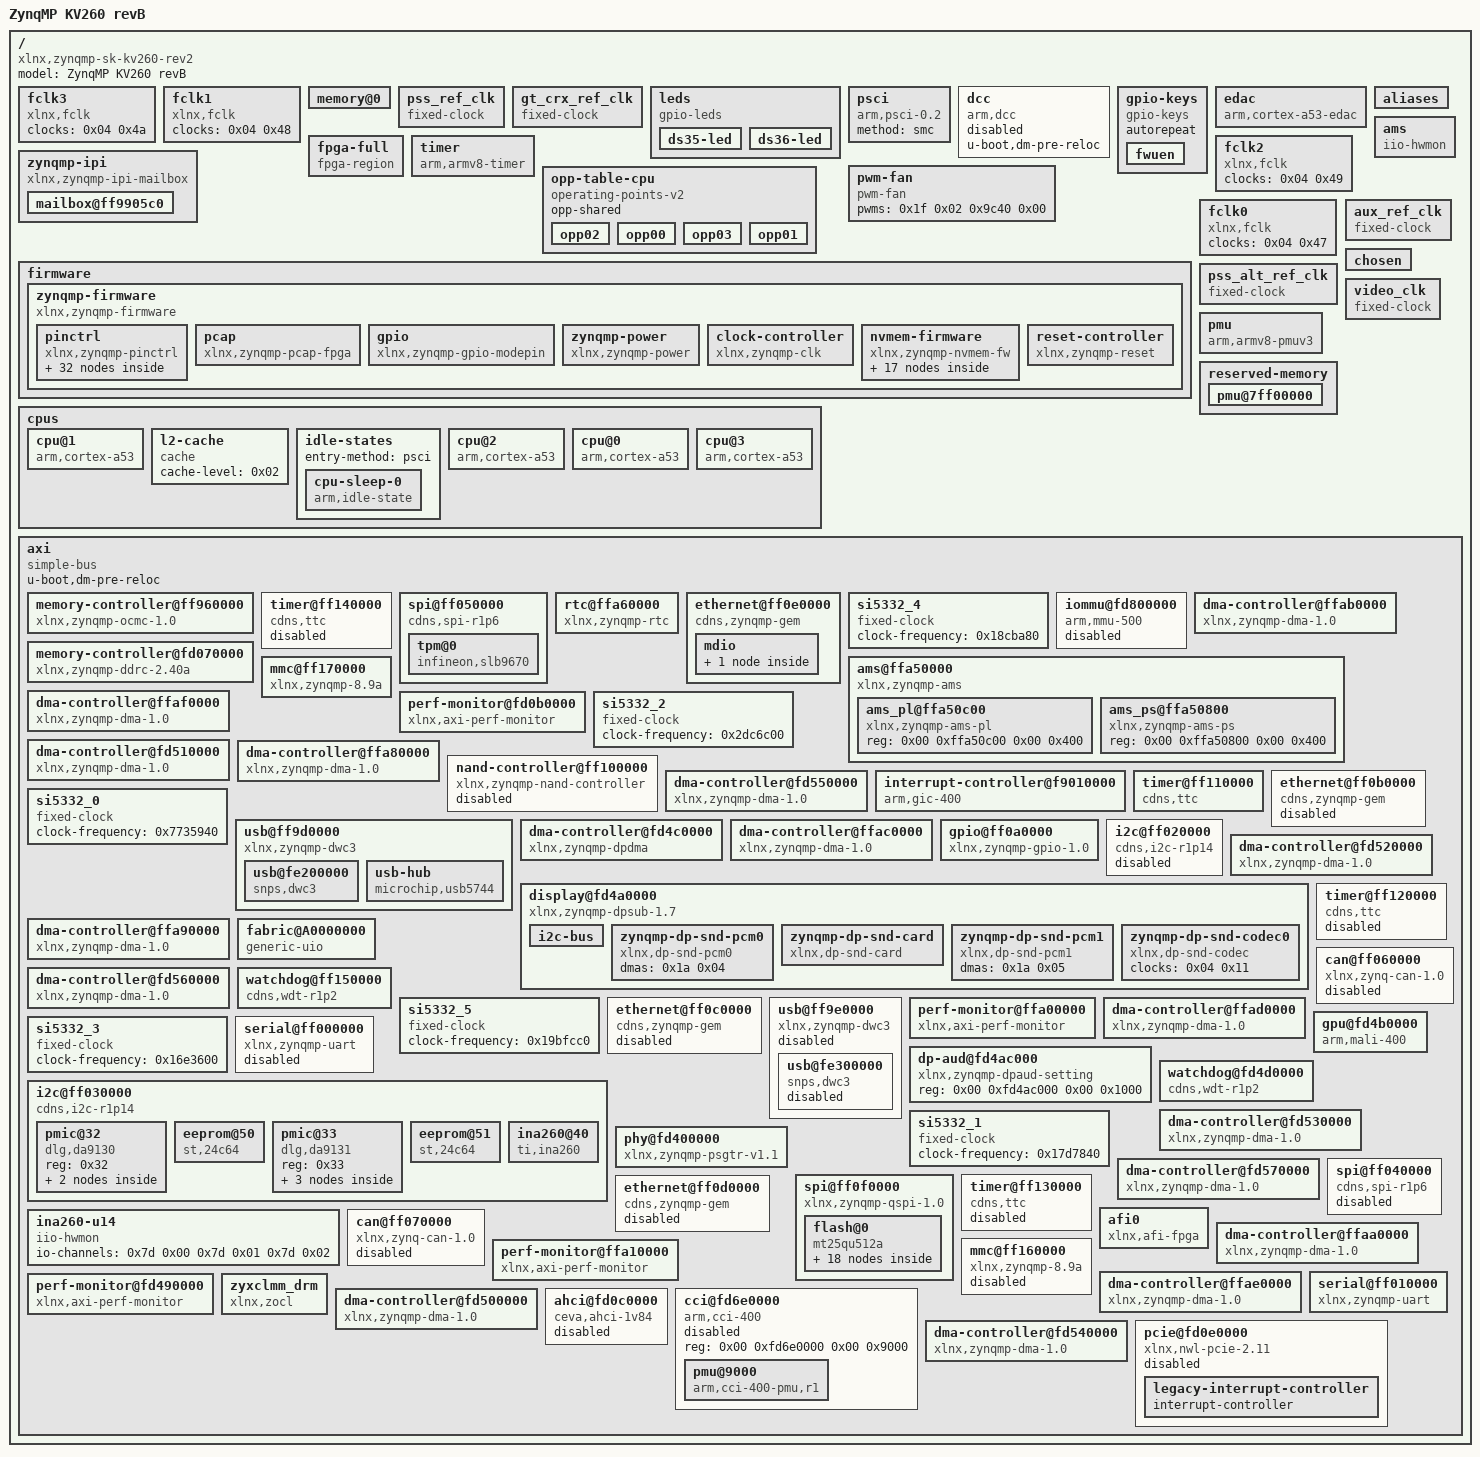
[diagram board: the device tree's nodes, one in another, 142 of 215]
/dts-v1/;

/ {
	#address-cells = <0x02>;
	model = "ZynqMP KV260 revB";
	#size-cells = <0x02>;
	compatible = "xlnx,zynqmp-sk-kv260-rev2\0xlnx,zynqmp-sk-kv260-rev1\0xlnx,zynqmp-sk-kv260-revB\0xlnx,zynqmp-sk-kv260\0xlnx,zynqmp";

	fclk3 {
		clocks = <0x04 0x4a>;
		compatible = "xlnx,fclk";
		status = "okay";
		phandle = <0x79>;
	};

	fclk1 {
		clocks = <0x04 0x48>;
		compatible = "xlnx,fclk";
		status = "okay";
		phandle = <0x77>;
	};

	memory@0 {
		device_type = "memory";
		reg = <0x00 0x00 0x00 0x7ff00000 0x08 0x00 0x00 0x80000000>;
	};

	pss_ref_clk {
		u-boot,dm-pre-reloc;
		#clock-cells = <0x00>;
		clock-frequency = <0x1fca055>;
		compatible = "fixed-clock";
		phandle = <0x0b>;
	};

	gt_crx_ref_clk {
		u-boot,dm-pre-reloc;
		#clock-cells = <0x00>;
		clock-frequency = <0x66ff300>;
		compatible = "fixed-clock";
		phandle = <0x0f>;
	};

	leds {
		compatible = "gpio-leds";

		ds35-led {
			linux,default-trigger = "heartbeat";
			label = "heartbeat";
			gpios = <0x14 0x07 0x00>;
		};

		ds36-led {
			label = "vbus_det";
			default-state = "on";
			gpios = <0x14 0x08 0x00>;
		};
	};

	psci {
		method = "smc";
		compatible = "arm,psci-0.2";
	};

	dcc {
		u-boot,dm-pre-reloc;
		compatible = "arm,dcc";
		status = "disabled";
		phandle = <0x21>;
	};

	gpio-keys {
		autorepeat;
		compatible = "gpio-keys";

		fwuen {
			autorepeat;
			wakeup-source;
			label = "fwuen";
			linux,code = <0x100>;
			gpios = <0x14 0x0c 0x01>;
		};
	};

	edac {
		compatible = "arm,cortex-a53-edac";
	};

	fpga-full {
		fpga-mgr = <0x10>;
		#address-cells = <0x02>;
		firmware-name = "k26-starter-kits.bit.bin";
		resets = <0x11 0x74 0x11 0x75 0x11 0x76 0x11 0x77>;
		#size-cells = <0x02>;
		compatible = "fpga-region";
		ranges;
		phandle = <0x35>;
	};

	timer {
		interrupts = <0x01 0x0d 0xf08 0x01 0x0e 0xf08 0x01 0x0b 0xf08 0x01 0x0a 0xf08>;
		interrupt-parent = <0x05>;
		compatible = "arm,armv8-timer";
	};

	fclk2 {
		clocks = <0x04 0x49>;
		compatible = "xlnx,fclk";
		status = "okay";
		phandle = <0x78>;
	};

	zynqmp-ipi {
		#address-cells = <0x02>;
		xlnx,ipi-id = <0x00>;
		u-boot,dm-pre-reloc;
		interrupts = <0x00 0x23 0x04>;
		#size-cells = <0x02>;
		interrupt-parent = <0x05>;
		compatible = "xlnx,zynqmp-ipi-mailbox";
		ranges;
		phandle = <0x20>;

		mailbox@ff9905c0 {
			xlnx,ipi-id = <0x04>;
			reg-names = "local_request_region\0local_response_region\0remote_request_region\0remote_response_region";
			u-boot,dm-pre-reloc;
			#mbox-cells = <0x01>;
			reg = <0x00 0xff9905c0 0x00 0x20 0x00 0xff9905e0 0x00 0x20 0x00 0xff990e80 0x00 0x20 0x00 0xff990ea0 0x00 0x20>;
			phandle = <0x0a>;
		};
	};

	opp-table-cpu {
		opp-shared;
		compatible = "operating-points-v2";
		phandle = <0x01>;

		opp02 {
			opp-microvolt = <0xf4240>;
			opp-hz = <0x00 0x1a7daf1c>;
			clock-latency-ns = <0x7a120>;
		};

		opp00 {
			opp-microvolt = <0xf4240>;
			opp-hz = <0x00 0x4f790d55>;
			clock-latency-ns = <0x7a120>;
		};

		opp03 {
			opp-microvolt = <0xf4240>;
			opp-hz = <0x00 0x13de4355>;
			clock-latency-ns = <0x7a120>;
		};

		opp01 {
			opp-microvolt = <0xf4240>;
			opp-hz = <0x00 0x27bc86aa>;
			clock-latency-ns = <0x7a120>;
		};
	};

	pwm-fan {
		compatible = "pwm-fan";
		status = "okay";
		pwms = <0x1f 0x02 0x9c40 0x00>;
	};

	aliases {
		spi2 = "/axi/spi@ff050000";
		i2c1 = "/axi/i2c@ff030000";
		spi0 = "/axi/spi@ff0f0000";
		mmc1 = "/axi/mmc@ff170000";
		usb1 = "/axi/usb@ff9e0000";
		nvmem0 = "/axi/i2c@ff030000/eeprom@50";
		serial1 = "/axi/serial@ff010000";
		rtc0 = "/axi/rtc@ffa60000";
		spi1 = "/axi/spi@ff040000";
		i2c0 = "/axi/i2c@ff020000";
		mmc0 = "/axi/mmc@ff160000";
		usb0 = "/axi/usb@ff9d0000";
		nvmem1 = "/axi/i2c@ff030000/eeprom@51";
		serial2 = "/dcc";
		serial0 = "/axi/serial@ff000000";
	};

	firmware {

		zynqmp-firmware {
			method = "smc";
			u-boot,dm-pre-reloc;
			#power-domain-cells = <0x01>;
			compatible = "xlnx,zynqmp-firmware";
			phandle = <0x12>;

			pinctrl {
				compatible = "xlnx,zynqmp-pinctrl";
				status = "okay";
				phandle = <0x34>;

				usb0-default {
					phandle = <0x81>;

					mux {
						function = "usb0";
						groups = "usb0_0_grp";
					};

					conf {
						groups = "usb0_0_grp";
						power-source = <0x01>;
					};

					conf-tx {
						pins = "MIO54\0MIO56\0MIO57\0MIO58\0MIO59\0MIO60\0MIO61\0MIO62\0MIO63";
						drive-strength = <0x04>;
						bias-disable;
						slew-rate = <0x01>;
					};

					conf-rx {
						pins = "MIO52\0MIO53\0MIO55";
						drive-strength = <0x0c>;
						bias-high-impedance;
						slew-rate = <0x00>;
					};
				};

				sdhci1-default {
					phandle = <0x82>;

					mux-cd {
						function = "sdio1_cd";
						groups = "sdio1_cd_0_grp";
					};

					conf-cd {
						bias-high-impedance;
						slew-rate = <0x01>;
						bias-pull-up;
						groups = "sdio1_cd_0_grp";
						power-source = <0x01>;
					};

					mux {
						function = "sdio1";
						groups = "sdio1_0_grp";
					};

					conf {
						bias-disable;
						slew-rate = <0x01>;
						groups = "sdio1_0_grp";
						power-source = <0x01>;
					};
				};

				i2c1-default {
					phandle = <0x7b>;

					mux {
						function = "i2c1";
						groups = "i2c1_6_grp";
					};

					conf {
						slew-rate = <0x01>;
						bias-pull-up;
						groups = "i2c1_6_grp";
						power-source = <0x01>;
					};
				};

				uart1-default {
					phandle = <0x85>;

					mux {
						function = "uart1";
						groups = "uart1_9_grp";
					};

					conf {
						drive-strength = <0x0c>;
						slew-rate = <0x01>;
						groups = "uart1_9_grp";
						power-source = <0x01>;
					};

					conf-tx {
						pins = "MIO36";
						bias-disable;
					};

					conf-rx {
						pins = "MIO37";
						bias-high-impedance;
					};
				};

				i2c1-gpio {
					phandle = <0x7c>;

					mux {
						function = "gpio0";
						groups = "gpio0_24_grp\0gpio0_25_grp";
					};

					conf {
						slew-rate = <0x01>;
						groups = "gpio0_24_grp\0gpio0_25_grp";
						power-source = <0x01>;
					};
				};

				gem3-default {
					phandle = <0x83>;

					mux {
						function = "ethernet3";
						groups = "ethernet3_0_grp";
					};

					conf-bootstrap {
						low-power-disable;
						pins = "MIO71\0MIO73\0MIO75";
						bias-disable;
					};

					conf {
						slew-rate = <0x01>;
						groups = "ethernet3_0_grp";
						power-source = <0x01>;
					};

					mux-mdio {
						function = "mdio3";
						groups = "mdio3_0_grp";
					};

					conf-mdio {
						bias-disable;
						slew-rate = <0x01>;
						groups = "mdio3_0_grp";
						power-source = <0x01>;
					};

					conf-tx {
						pins = "MIO64\0MIO65\0MIO66\0MIO67\0MIO68\0MIO69";
						bias-disable;
						low-power-enable;
					};

					conf-rx {
						low-power-disable;
						pins = "MIO70\0MIO72\0MIO74";
						bias-high-impedance;
					};
				};

				sdhci0-default {
					phandle = <0x17>;

					mux {
						function = "sdio0";
						groups = "sdio0_0_grp";
					};

					conf {
						bias-disable;
						slew-rate = <0x01>;
						groups = "sdio0_0_grp";
						power-source = <0x01>;
					};
				};
			};

			pcap {
				compatible = "xlnx,zynqmp-pcap-fpga";
				phandle = <0x10>;
			};

			gpio {
				gpio-controller;
				label = "modepin";
				compatible = "xlnx,zynqmp-gpio-modepin";
				phandle = <0x18>;
				#gpio-cells = <0x02>;
			};

			zynqmp-power {
				u-boot,dm-pre-reloc;
				interrupts = <0x00 0x23 0x04>;
				interrupt-parent = <0x05>;
				compatible = "xlnx,zynqmp-power";
				phandle = <0x22>;
				mboxes = <0x0a 0x00 0x0a 0x01>;
				mbox-names = "tx\0rx";
			};

			clock-controller {
				clock-names = "pss_ref_clk\0video_clk\0pss_alt_ref_clk\0aux_ref_clk\0gt_crx_ref_clk";
				u-boot,dm-pre-reloc;
				clocks = <0x0b 0x0c 0x0d 0x0e 0x0f>;
				#clock-cells = <0x01>;
				compatible = "xlnx,zynqmp-clk";
				phandle = <0x04>;
			};

			nvmem-firmware {
				#address-cells = <0x01>;
				#size-cells = <0x01>;
				compatible = "xlnx,zynqmp-nvmem-fw";

				efuse-usr3@2c {
					reg = <0x2c 0x04>;
					phandle = <0x28>;
				};

				efuse-ppk1hash@d0 {
					reg = <0xd0 0x30>;
					phandle = <0x33>;
				};

				efuse-sec@58 {
					reg = <0x58 0x04>;
					phandle = <0x30>;
				};

				efuse-ppk0hash@a0 {
					reg = <0xa0 0x30>;
					phandle = <0x32>;
				};

				efuse-usr1@24 {
					reg = <0x24 0x04>;
					phandle = <0x26>;
				};

				efuse-miscusr@40 {
					reg = <0x40 0x04>;
					phandle = <0x2d>;
				};

				efuse-usr6@38 {
					reg = <0x38 0x04>;
					phandle = <0x2b>;
				};

				efuse-usr4@30 {
					reg = <0x30 0x04>;
					phandle = <0x29>;
				};

				efuse-dna@c {
					reg = <0x0c 0x0c>;
					phandle = <0x24>;
				};

				soc-revision@0 {
					reg = <0x00 0x04>;
					phandle = <0x23>;
				};

				efuse-spkid@5c {
					reg = <0x5c 0x04>;
					phandle = <0x31>;
				};

				efuse-chash@50 {
					reg = <0x50 0x04>;
					phandle = <0x2e>;
				};

				efuse-pufmisc@54 {
					reg = <0x54 0x04>;
					phandle = <0x2f>;
				};

				efuse-usr7@3c {
					reg = <0x3c 0x04>;
					phandle = <0x2c>;
				};

				efuse-usr2@28 {
					reg = <0x28 0x04>;
					phandle = <0x27>;
				};

				efuse-usr0@20 {
					reg = <0x20 0x04>;
					phandle = <0x25>;
				};

				efuse-usr5@34 {
					reg = <0x34 0x04>;
					phandle = <0x2a>;
				};
			};

			reset-controller {
				#reset-cells = <0x01>;
				compatible = "xlnx,zynqmp-reset";
				phandle = <0x11>;
			};
		};
	};

	fclk0 {
		clocks = <0x04 0x47>;
		compatible = "xlnx,fclk";
		status = "okay";
		phandle = <0x76>;
	};

	pss_alt_ref_clk {
		u-boot,dm-pre-reloc;
		#clock-cells = <0x00>;
		clock-frequency = <0x00>;
		compatible = "fixed-clock";
		phandle = <0x0d>;
	};

	ams {
		io-channels = <0x1e 0x00 0x1e 0x01 0x1e 0x02 0x1e 0x03 0x1e 0x04 0x1e 0x05 0x1e 0x06 0x1e 0x07 0x1e 0x08 0x1e 0x09 0x1e 0x0a 0x1e 0x0b 0x1e 0x0c 0x1e 0x0d 0x1e 0x0e 0x1e 0x0f 0x1e 0x10 0x1e 0x11 0x1e 0x12 0x1e 0x13 0x1e 0x14 0x1e 0x15 0x1e 0x16 0x1e 0x17 0x1e 0x18 0x1e 0x19 0x1e 0x1a 0x1e 0x1b 0x1e 0x1c 0x1e 0x1d>;
		compatible = "iio-hwmon";
	};

	aux_ref_clk {
		u-boot,dm-pre-reloc;
		#clock-cells = <0x00>;
		clock-frequency = <0x19bfcc0>;
		compatible = "fixed-clock";
		phandle = <0x0e>;
	};

	chosen {
		linux,initrd-end = <0x00 0x78fffb2d>;
		bootargs = " root=LABEL=writable rootwait earlycon console=ttyPS1,115200 console=tty1 clk_ignore_unused uio_pdrv_genirq.of_id=generic-uio xilinx_tsn_ep.st_pcp=4 cma=1000M ";
		linux,initrd-start = <0x00 0x75de5000>;
		stdout-path = "serial1:115200n8";
	};

	video_clk {
		u-boot,dm-pre-reloc;
		#clock-cells = <0x00>;
		clock-frequency = <0x19bfcc0>;
		compatible = "fixed-clock";
		phandle = <0x0c>;
	};

	pmu {
		interrupt-affinity = <0x06 0x07 0x08 0x09>;
		interrupts = <0x00 0x8f 0x04 0x00 0x90 0x04 0x00 0x91 0x04 0x00 0x92 0x04>;
		interrupt-parent = <0x05>;
		compatible = "arm,armv8-pmuv3";
	};

	cpus {
		#address-cells = <0x01>;
		#size-cells = <0x00>;

		cpu@1 {
			cpu-idle-states = <0x02>;
			device_type = "cpu";
			compatible = "arm,cortex-a53";
			next-level-cache = <0x03>;
			reg = <0x01>;
			enable-method = "psci";
			phandle = <0x07>;
			operating-points-v2 = <0x01>;
		};

		l2-cache {
			cache-level = <0x02>;
			compatible = "cache";
			phandle = <0x03>;
		};

		idle-states {
			entry-method = "psci";

			cpu-sleep-0 {
				entry-latency-us = <0x12c>;
				local-timer-stop;
				exit-latency-us = <0x258>;
				arm,psci-suspend-param = <0x40000000>;
				compatible = "arm,idle-state";
				phandle = <0x02>;
				min-residency-us = <0x2710>;
			};
		};

		cpu@2 {
			cpu-idle-states = <0x02>;
			device_type = "cpu";
			compatible = "arm,cortex-a53";
			next-level-cache = <0x03>;
			reg = <0x02>;
			enable-method = "psci";
			phandle = <0x08>;
			operating-points-v2 = <0x01>;
		};

		cpu@0 {
			clocks = <0x04 0x0a>;
			cpu-idle-states = <0x02>;
			device_type = "cpu";
			compatible = "arm,cortex-a53";
			next-level-cache = <0x03>;
			reg = <0x00>;
			enable-method = "psci";
			phandle = <0x06>;
			operating-points-v2 = <0x01>;
		};

		cpu@3 {
			cpu-idle-states = <0x02>;
			device_type = "cpu";
			compatible = "arm,cortex-a53";
			next-level-cache = <0x03>;
			reg = <0x03>;
			enable-method = "psci";
			phandle = <0x09>;
			operating-points-v2 = <0x01>;
		};
	};

	__symbols__ {
		efuse_usr0 = "/firmware/zynqmp-firmware/nvmem-firmware/efuse-usr0@20";
		fpd_dma_chan3 = "/axi/dma-controller@fd520000";
		mdio = "/axi/ethernet@ff0e0000/mdio";
		efuse_ppk0hash = "/firmware/zynqmp-firmware/nvmem-firmware/efuse-ppk0hash@a0";
		ams_ps = "/axi/ams@ffa50000/ams_ps@ffa50800";
		nand0 = "/axi/nand-controller@ff100000";
		fclk3 = "/fclk3";
		zynqmp_pcap = "/firmware/zynqmp-firmware/pcap";
		si5332_4 = "/axi/si5332_4";
		CPU_SLEEP_0 = "/cpus/idle-states/cpu-sleep-0";
		efuse_chash = "/firmware/zynqmp-firmware/nvmem-firmware/efuse-chash@50";
		ipi_mailbox_pmu1 = "/zynqmp-ipi/mailbox@ff9905c0";
		i2c1 = "/axi/i2c@ff030000";
		fpd_dma_chan1 = "/axi/dma-controller@fd500000";
		efuse_sec = "/firmware/zynqmp-firmware/nvmem-firmware/efuse-sec@58";
		pinctrl_sdhci1_default = "/firmware/zynqmp-firmware/pinctrl/sdhci1-default";
		ttc3 = "/axi/timer@ff140000";
		da9131 = "/axi/i2c@ff030000/pmic@33";
		qspi = "/axi/spi@ff0f0000";
		zynqmp_dp_snd_pcm0 = "/axi/display@fd4a0000/zynqmp-dp-snd-pcm0";
		fclk1 = "/fclk1";
		gpu = "/axi/gpu@fd4b0000";
		spi0 = "/axi/spi@ff040000";
		si5332_2 = "/axi/si5332_2";
		lpd_dma_chan8 = "/axi/dma-controller@ffaf0000";
		pinctrl_i2c1_default = "/firmware/zynqmp-firmware/pinctrl/i2c1-default";
		efuse_usr7 = "/firmware/zynqmp-firmware/nvmem-firmware/efuse-usr7@3c";
		gpio = "/axi/gpio@ff0a0000";
		zynqmp_clk = "/firmware/zynqmp-firmware/clock-controller";
		usb1 = "/axi/usb@ff9e0000";
		ttc1 = "/axi/timer@ff120000";
		amba = "/axi";
		usb5744 = "/axi/usb@ff9d0000/usb-hub";
		efuse_spkid = "/firmware/zynqmp-firmware/nvmem-firmware/efuse-spkid@5c";
		pss_ref_clk = "/pss_ref_clk";
		si5332_0 = "/axi/si5332_0";
		lpd_dma_chan6 = "/axi/dma-controller@ffad0000";
		efuse_usr5 = "/firmware/zynqmp-firmware/nvmem-firmware/efuse-usr5@34";
		fpd_dma_chan8 = "/axi/dma-controller@fd570000";
		efuse_ppk1hash = "/firmware/zynqmp-firmware/nvmem-firmware/efuse-ppk1hash@d0";
		gem3 = "/axi/ethernet@ff0e0000";
		cpu3 = "/cpus/cpu@3";
		zynqmp_dpaud_setting = "/axi/dp-aud@fd4ac000";
		dwc3_0 = "/axi/usb@ff9d0000/usb@fe200000";
		da9131_buck2 = "/axi/i2c@ff030000/pmic@33/regulators/buck2";
		perf_monitor_cci = "/axi/perf-monitor@fd490000";
		lpd_dma_chan4 = "/axi/dma-controller@ffab0000";
		efuse_usr3 = "/firmware/zynqmp-firmware/nvmem-firmware/efuse-usr3@2c";
		fpd_dma_chan6 = "/axi/dma-controller@fd550000";
		gt_crx_ref_clk = "/gt_crx_ref_clk";
		gic = "/axi/interrupt-controller@f9010000";
		gem1 = "/axi/ethernet@ff0c0000";
		sata = "/axi/ahci@fd0c0000";
		cpu1 = "/cpus/cpu@1";
		xilinx_ams = "/axi/ams@ffa50000";
		pinctrl_gem3_default = "/firmware/zynqmp-firmware/pinctrl/gem3-default";
		perf_monitor_lpd = "/axi/perf-monitor@ffa10000";
		uart0 = "/axi/serial@ff000000";
		zynqmp_dp_snd_codec0 = "/axi/display@fd4a0000/zynqmp-dp-snd-codec0";
		dcc = "/dcc";
		lpd_dma_chan2 = "/axi/dma-controller@ffa90000";
		ams_pl = "/axi/ams@ffa50000/ams_pl@ffa50c00";
		L2 = "/cpus/l2-cache";
		efuse_usr1 = "/firmware/zynqmp-firmware/nvmem-firmware/efuse-usr1@24";
		fpd_dma_chan4 = "/axi/dma-controller@fd530000";
		cci = "/axi/cci@fd6e0000";
		perf_monitor_ddr = "/axi/perf-monitor@fd0b0000";
		cpu_opp_table = "/opp-table-cpu";
		can0 = "/axi/can@ff060000";
		pcie = "/axi/pcie@fd0e0000";
		sdhci0 = "/axi/mmc@ff160000";
		perf_monitor_ocm = "/axi/perf-monitor@ffa00000";
		si5332_5 = "/axi/si5332_5";
		watchdog0 = "/axi/watchdog@fd4d0000";
		fpga_full = "/fpga-full";
		pinctrl_sdhci0_default = "/firmware/zynqmp-firmware/pinctrl/sdhci0-default";
		fpd_dma_chan2 = "/axi/dma-controller@fd510000";
		zynqmp_firmware = "/firmware/zynqmp-firmware";
		zynqmp_dp_snd_pcm1 = "/axi/display@fd4a0000/zynqmp-dp-snd-pcm1";
		fclk2 = "/fclk2";
		spi1 = "/axi/spi@ff050000";
		si5332_3 = "/axi/si5332_3";
		da9130_buck1 = "/axi/i2c@ff030000/pmic@32/regulators/buck1";
		ocm = "/axi/memory-controller@ff960000";
		pinctrl_i2c1_gpio = "/firmware/zynqmp-firmware/pinctrl/i2c1-gpio";
		eeprom = "/axi/i2c@ff030000/eeprom@50";
		pinctrl_uart1_default = "/firmware/zynqmp-firmware/pinctrl/uart1-default";
		i2c0 = "/axi/i2c@ff020000";
		pmu_region = "/reserved-memory/pmu@7ff00000";
		ttc2 = "/axi/timer@ff130000";
		soc_revision = "/firmware/zynqmp-firmware/nvmem-firmware/soc-revision@0";
		da9130 = "/axi/i2c@ff030000/pmic@32";
		fclk0 = "/fclk0";
		u14 = "/axi/i2c@ff030000/ina260@40";
		pss_alt_ref_clk = "/pss_alt_ref_clk";
		si5332_1 = "/axi/si5332_1";
		lpd_dma_chan7 = "/axi/dma-controller@ffae0000";
		efuse_usr6 = "/firmware/zynqmp-firmware/nvmem-firmware/efuse-usr6@38";
		efuse_dna = "/firmware/zynqmp-firmware/nvmem-firmware/efuse-dna@c";
		aux_ref_clk = "/aux_ref_clk";
		psgtr = "/axi/phy@fd400000";
		usb0 = "/axi/usb@ff9d0000";
		ttc0 = "/axi/timer@ff110000";
		mc = "/axi/memory-controller@fd070000";
		zynqmp_dpsub = "/axi/display@fd4a0000";
		pinctrl0 = "/firmware/zynqmp-firmware/pinctrl";
		dwc3_1 = "/axi/usb@ff9e0000/usb@fe300000";
		phy0 = "/axi/ethernet@ff0e0000/mdio/ethernet-phy@1";
		lpd_dma_chan5 = "/axi/dma-controller@ffac0000";
		zynqmp_ipi = "/zynqmp-ipi";
		efuse_usr4 = "/firmware/zynqmp-firmware/nvmem-firmware/efuse-usr4@30";
		fpd_dma_chan7 = "/axi/dma-controller@fd560000";
		video_clk = "/video_clk";
		gem2 = "/axi/ethernet@ff0d0000";
		efuse_pufmisc = "/firmware/zynqmp-firmware/nvmem-firmware/efuse-pufmisc@54";
		zynqmp_dpdma = "/axi/dma-controller@fd4c0000";
		cpu2 = "/cpus/cpu@2";
		uart1 = "/axi/serial@ff010000";
		da9131_buck1 = "/axi/i2c@ff030000/pmic@33/regulators/buck1";
		efuse_miscusr = "/firmware/zynqmp-firmware/nvmem-firmware/efuse-miscusr@40";
		lpd_dma_chan3 = "/axi/dma-controller@ffaa0000";
		efuse_usr2 = "/firmware/zynqmp-firmware/nvmem-firmware/efuse-usr2@28";
		fpd_dma_chan5 = "/axi/dma-controller@fd540000";
		eeprom_cc = "/axi/i2c@ff030000/eeprom@51";
		zynqmp_dp_snd_card0 = "/axi/display@fd4a0000/zynqmp-dp-snd-card";
		zynqmp_power = "/firmware/zynqmp-firmware/zynqmp-power";
		can1 = "/axi/can@ff070000";
		gem0 = "/axi/ethernet@ff0b0000";
		pinctrl_usb0_default = "/firmware/zynqmp-firmware/pinctrl/usb0-default";
		pcie_intc = "/axi/pcie@fd0e0000/legacy-interrupt-controller";
		sdhci1 = "/axi/mmc@ff170000";
		rtc = "/axi/rtc@ffa60000";
		smmu = "/axi/iommu@fd800000";
		lpd_watchdog = "/axi/watchdog@ff150000";
		modepin_gpio = "/firmware/zynqmp-firmware/gpio";
		cpu0 = "/cpus/cpu@0";
		zynqmp_reset = "/firmware/zynqmp-firmware/reset-controller";
		lpd_dma_chan1 = "/axi/dma-controller@ffa80000";
	};

	reserved-memory {
		#address-cells = <0x02>;
		#size-cells = <0x02>;
		ranges;

		pmu@7ff00000 {
			reg = <0x00 0x7ff00000 0x00 0x100000>;
			phandle = <0x7a>;
			no-map;
		};
	};

	axi {
		#address-cells = <0x02>;
		u-boot,dm-pre-reloc;
		#size-cells = <0x02>;
		compatible = "simple-bus";
		ranges;
		phandle = <0x36>;

		memory-controller@ff960000 {
			interrupts = <0x00 0x0a 0x04>;
			interrupt-parent = <0x05>;
			compatible = "xlnx,zynqmp-ocmc-1.0";
			reg = <0x00 0xff960000 0x00 0x1000>;
			phandle = <0x5a>;
		};

		timer@ff140000 {
			power-domains = <0x12 0x1b>;
			timer-width = <0x20>;
			interrupts = <0x00 0x2d 0x04 0x00 0x2e 0x04 0x00 0x2f 0x04>;
			clocks = <0x04 0x1f>;
			interrupt-parent = <0x05>;
			compatible = "cdns,ttc";
			status = "disabled";
			reg = <0x00 0xff140000 0x00 0x1000>;
			phandle = <0x69>;
		};

		spi@ff050000 {
			power-domains = <0x12 0x24>;
			#address-cells = <0x01>;
			num-cs = <0x01>;
			clock-names = "ref_clk\0pclk";
			interrupts = <0x00 0x14 0x04>;
			clocks = <0x04 0x3b 0x04 0x1f>;
			#size-cells = <0x00>;
			interrupt-parent = <0x05>;
			label = "TPM";
			compatible = "cdns,spi-r1p6";
			status = "okay";
			reg = <0x00 0xff050000 0x00 0x1000>;
			phandle = <0x66>;

			tpm@0 {
				spi-max-frequency = <0x11a49a0>;
				compatible = "infineon,slb9670\0tcg,tpm_tis-spi";
				reg = <0x00>;
			};
		};

		rtc@ffa60000 {
			calibration = <0x7fff>;
			interrupts = <0x00 0x1a 0x04 0x00 0x1b 0x04>;
			interrupt-parent = <0x05>;
			compatible = "xlnx,zynqmp-rtc";
			status = "okay";
			interrupt-names = "alarm\0sec";
			reg = <0x00 0xffa60000 0x00 0x100>;
			phandle = <0x61>;
		};

		ethernet@ff0e0000 {
			power-domains = <0x12 0x20>;
			iommus = <0x13 0x877>;
			pinctrl-names = "default";
			#address-cells = <0x01>;
			phy-mode = "rgmii-id";
			pinctrl-0 = <0x83>;
			clock-names = "pclk\0hclk\0tx_clk\0rx_clk\0tsu_clk";
			assigned-clocks = <0x04 0x2c>;
			assigned-clock-rates = <0xee6b280>;
			resets = <0x11 0x20>;
			interrupts = <0x00 0x3f 0x04 0x00 0x3f 0x04>;
			clocks = <0x04 0x1f 0x04 0x6b 0x04 0x30 0x04 0x34 0x04 0x2c>;
			#size-cells = <0x00>;
			interrupt-parent = <0x05>;
			compatible = "cdns,zynqmp-gem\0cdns,gem";
			status = "okay";
			reg = <0x00 0xff0e0000 0x00 0x1000>;
			phandle = <0x50>;
			phy-handle = <0x84>;
			reset-names = "gem3_rst";

			mdio {
				#address-cells = <0x01>;
				#size-cells = <0x00>;
				phandle = <0x8a>;

				ethernet-phy@1 {
					reset-deassert-us = <0x118>;
					ti,dp83867-rxctrl-strap-quirk;
					ti,tx-internal-delay = <0x0a>;
					#phy-cells = <0x01>;
					reset-assert-us = <0x64>;
					reset-gpios = <0x14 0x26 0x01>;
					compatible = "ethernet-phy-id2000.a231";
					ti,fifo-depth = <0x01>;
					ti,rx-internal-delay = <0x08>;
					reg = <0x01>;
					phandle = <0x84>;
				};
			};
		};

		si5332_4 {
			#clock-cells = <0x00>;
			clock-frequency = <0x18cba80>;
			compatible = "fixed-clock";
			phandle = <0x7f>;
		};

		iommu@fd800000 {
			#global-interrupts = <0x01>;
			interrupts = <0x00 0x9b 0x04 0x00 0x9b 0x04 0x00 0x9b 0x04 0x00 0x9b 0x04 0x00 0x9b 0x04 0x00 0x9b 0x04 0x00 0x9b 0x04 0x00 0x9b 0x04 0x00 0x9b 0x04 0x00 0x9b 0x04 0x00 0x9b 0x04 0x00 0x9b 0x04 0x00 0x9b 0x04 0x00 0x9b 0x04 0x00 0x9b 0x04 0x00 0x9b 0x04 0x00 0x9b 0x04>;
			interrupt-parent = <0x05>;
			#iommu-cells = <0x01>;
			compatible = "arm,mmu-500";
			status = "disabled";
			reg = <0x00 0xfd800000 0x00 0x20000>;
			phandle = <0x13>;
		};

		dma-controller@ffab0000 {
			power-domains = <0x12 0x2b>;
			clock-names = "clk_main\0clk_apb";
			interrupts = <0x00 0x50 0x04>;
			clocks = <0x04 0x44 0x04 0x1f>;
			interrupt-parent = <0x05>;
			xlnx,bus-width = <0x40>;
			compatible = "xlnx,zynqmp-dma-1.0";
			status = "okay";
			reg = <0x00 0xffab0000 0x00 0x1000>;
			phandle = <0x46>;
			#dma-cells = <0x01>;
		};

		ams@ffa50000 {
			#address-cells = <0x02>;
			reg-names = "ams-base";
			interrupts = <0x00 0x38 0x04>;
			clocks = <0x04 0x46>;
			#io-channel-cells = <0x01>;
			#size-cells = <0x02>;
			interrupt-parent = <0x05>;
			compatible = "xlnx,zynqmp-ams";
			ranges;
			status = "okay";
			interrupt-names = "ams-irq";
			reg = <0x00 0xffa50000 0x00 0x800>;
			phandle = <0x1e>;

			ams_pl@ffa50c00 {
				compatible = "xlnx,zynqmp-ams-pl";
				status = "okay";
				reg = <0x00 0xffa50c00 0x00 0x400>;
				phandle = <0x73>;
			};

			ams_ps@ffa50800 {
				compatible = "xlnx,zynqmp-ams-ps";
				status = "okay";
				reg = <0x00 0xffa50800 0x00 0x400>;
				phandle = <0x72>;
			};
		};

		memory-controller@fd070000 {
			interrupts = <0x00 0x70 0x04>;
			interrupt-parent = <0x05>;
			compatible = "xlnx,zynqmp-ddrc-2.40a";
			reg = <0x00 0xfd070000 0x00 0x30000>;
			phandle = <0x4b>;
		};

		mmc@ff170000 {
			power-domains = <0x12 0x28>;
			iommus = <0x13 0x871>;
			pinctrl-names = "default";
			clock-output-names = "clk_out_sd1\0clk_in_sd1";
			clk-phase-sd-hs = <0x7e 0x3c>;
			xlnx,mio-bank = <0x01>;
			pinctrl-0 = <0x82>;
			clock-names = "clk_xin\0clk_ahb";
			assigned-clocks = <0x04 0x37>;
			bus-width = <0x08>;
			u-boot,dm-pre-reloc;
			clk-phase-uhs-ddr50 = <0x7e 0x30>;
			assigned-clock-rates = <0xb2cfe8b>;
			resets = <0x11 0x27>;
			interrupts = <0x00 0x31 0x04>;
			clocks = <0x04 0x37 0x04 0x1f>;
			#clock-cells = <0x01>;
			interrupt-parent = <0x05>;
			no-1-8-v;
			clk-phase-uhs-sdr25 = <0x78 0x3c>;
			compatible = "xlnx,zynqmp-8.9a\0arasan,sdhci-8.9a";
			status = "okay";
			disable-wp;
			reg = <0x00 0xff170000 0x00 0x1000>;
			phandle = <0x64>;
		};

		dma-controller@ffaf0000 {
			power-domains = <0x12 0x2b>;
			clock-names = "clk_main\0clk_apb";
			interrupts = <0x00 0x54 0x04>;
			clocks = <0x04 0x44 0x04 0x1f>;
			interrupt-parent = <0x05>;
			xlnx,bus-width = <0x40>;
			compatible = "xlnx,zynqmp-dma-1.0";
			status = "okay";
			reg = <0x00 0xffaf0000 0x00 0x1000>;
			phandle = <0x4a>;
			#dma-cells = <0x01>;
		};

		perf-monitor@fd0b0000 {
			xlnx,metric-count-width = <0x20>;
			xlnx,have-sampled-metric-cnt = <0x01>;
			xlnx,enable-trace = <0x00>;
			xlnx,global-count-width = <0x20>;
			xlnx,enable-event-count = <0x01>;
			interrupts = <0x00 0x7b 0x04>;
			clocks = <0x04 0x1c>;
			xlnx,enable-profile = <0x00>;
			xlnx,metric-count-scale = <0x01>;
			interrupt-parent = <0x05>;
			xlnx,num-monitor-slots = <0x06>;
			compatible = "xlnx,axi-perf-monitor";
			xlnx,num-of-counters = <0x0a>;
			reg = <0x00 0xfd0b0000 0x00 0x10000>;
			phandle = <0x5c>;
			xlnx,metrics-sample-count-width = <0x20>;
			xlnx,enable-event-log = <0x00>;
		};

		si5332_2 {
			#clock-cells = <0x00>;
			clock-frequency = <0x2dc6c00>;
			compatible = "fixed-clock";
			phandle = <0x87>;
		};

		dma-controller@fd510000 {
			power-domains = <0x12 0x2a>;
			iommus = <0x13 0x14e9>;
			clock-names = "clk_main\0clk_apb";
			interrupts = <0x00 0x7d 0x04>;
			clocks = <0x04 0x13 0x04 0x1f>;
			interrupt-parent = <0x05>;
			xlnx,bus-width = <0x80>;
			compatible = "xlnx,zynqmp-dma-1.0";
			status = "okay";
			reg = <0x00 0xfd510000 0x00 0x1000>;
			phandle = <0x3b>;
			#dma-cells = <0x01>;
		};

		dma-controller@ffa80000 {
			power-domains = <0x12 0x2b>;
			clock-names = "clk_main\0clk_apb";
			interrupts = <0x00 0x4d 0x04>;
			clocks = <0x04 0x44 0x04 0x1f>;
			interrupt-parent = <0x05>;
			xlnx,bus-width = <0x40>;
			compatible = "xlnx,zynqmp-dma-1.0";
			status = "okay";
			reg = <0x00 0xffa80000 0x00 0x1000>;
			phandle = <0x43>;
			#dma-cells = <0x01>;
		};

		nand-controller@ff100000 {
			power-domains = <0x12 0x2c>;
			iommus = <0x13 0x872>;
			#address-cells = <0x01>;
			clock-names = "controller\0bus";
			interrupts = <0x00 0x0e 0x04>;
			clocks = <0x04 0x3c 0x04 0x1f>;
			#size-cells = <0x00>;
			interrupt-parent = <0x05>;
			compatible = "xlnx,zynqmp-nand-controller\0arasan,nfc-v3p10";
			status = "disabled";
			reg = <0x00 0xff100000 0x00 0x1000>;
			phandle = <0x4c>;
		};

		dma-controller@fd550000 {
			power-domains = <0x12 0x2a>;
			iommus = <0x13 0x14ed>;
			clock-names = "clk_main\0clk_apb";
			interrupts = <0x00 0x81 0x04>;
			clocks = <0x04 0x13 0x04 0x1f>;
			interrupt-parent = <0x05>;
			xlnx,bus-width = <0x80>;
			compatible = "xlnx,zynqmp-dma-1.0";
			status = "okay";
			reg = <0x00 0xfd550000 0x00 0x1000>;
			phandle = <0x3f>;
			#dma-cells = <0x01>;
		};

		interrupt-controller@f9010000 {
			interrupts = <0x01 0x09 0xf04>;
			interrupt-parent = <0x05>;
			compatible = "arm,gic-400";
			#interrupt-cells = <0x03>;
			reg = <0x00 0xf9010000 0x00 0x10000 0x00 0xf9020000 0x00 0x20000 0x00 0xf9040000 0x00 0x20000 0x00 0xf9060000 0x00 0x20000>;
			phandle = <0x05>;
			interrupt-controller;
		};

		timer@ff110000 {
			power-domains = <0x12 0x18>;
			timer-width = <0x20>;
			interrupts = <0x00 0x24 0x04 0x00 0x25 0x04 0x00 0x26 0x04>;
			clocks = <0x04 0x1f>;
			interrupt-parent = <0x05>;
			#pwm-cells = <0x03>;
			compatible = "cdns,ttc";
			status = "okay";
			reg = <0x00 0xff110000 0x00 0x1000>;
			phandle = <0x1f>;
		};

		si5332_0 {
			#clock-cells = <0x00>;
			clock-frequency = <0x7735940>;
			compatible = "fixed-clock";
			phandle = <0x80>;
		};

		ethernet@ff0b0000 {
			power-domains = <0x12 0x1d>;
			iommus = <0x13 0x874>;
			#address-cells = <0x01>;
			clock-names = "pclk\0hclk\0tx_clk\0rx_clk\0tsu_clk";
			assigned-clocks = <0x04 0x2c>;
			resets = <0x11 0x1d>;
			interrupts = <0x00 0x39 0x04 0x00 0x39 0x04>;
			clocks = <0x04 0x1f 0x04 0x68 0x04 0x2d 0x04 0x31 0x04 0x2c>;
			#size-cells = <0x00>;
			interrupt-parent = <0x05>;
			compatible = "cdns,zynqmp-gem\0cdns,gem";
			status = "disabled";
			reg = <0x00 0xff0b0000 0x00 0x1000>;
			phandle = <0x4d>;
			reset-names = "gem0_rst";
		};

		usb@ff9d0000 {
			power-domains = <0x12 0x16>;
			pinctrl-names = "default";
			#address-cells = <0x02>;
			phy-names = "usb3-phy";
			pinctrl-0 = <0x81>;
			clock-names = "bus_clk\0ref_clk";
			assigned-clocks = <0x04 0x20 0x04 0x22>;
			assigned-clock-rates = <0xee6b280 0x1312d00>;
			resets = <0x11 0x3b 0x11 0x3d 0x11 0x3f>;
			clocks = <0x04 0x20 0x04 0x22>;
			#size-cells = <0x02>;
			reset-gpios = <0x18 0x01 0x01>;
			compatible = "xlnx,zynqmp-dwc3";
			ranges;
			status = "okay";
			phys = <0x60 0x02 0x04 0x00 0x01>;
			reg = <0x00 0xff9d0000 0x00 0x100>;
			phandle = <0x6c>;
			reset-names = "usb_crst\0usb_hibrst\0usb_apbrst";

			usb@fe200000 {
				iommus = <0x13 0x860>;
				snps,quirk-frame-length-adjustment = <0x20>;
				snps,usb3_lpm_capable;
				snps,refclk_fladj;
				interrupts = <0x00 0x41 0x04 0x00 0x45 0x04 0x00 0x4b 0x04>;
				clocks = <0x04 0x22>;
				interrupt-parent = <0x05>;
				compatible = "snps,dwc3";
				status = "okay";
				interrupt-names = "dwc_usb3\0otg\0hiber";
				snps,enable_guctl1_ipd_quirk;
				snps,xhci-stream-quirk;
				reg = <0x00 0xfe200000 0x00 0x40000>;
				phandle = <0x6d>;
				dr_mode = "host";
				maximum-speed = "super-speed";
				snps,enable_guctl1_resume_quirk;
				snps,xhci-reset-on-resume;
			};

			usb-hub {
				i2c-bus = <0x52>;
				reset-gpios = <0x14 0x2c 0x01>;
				compatible = "microchip,usb5744";
				status = "okay";
				phandle = <0x89>;
			};
		};

		dma-controller@fd4c0000 {
			power-domains = <0x12 0x29>;
			iommus = <0x13 0xce4>;
			clock-names = "axi_clk";
			assigned-clocks = <0x04 0x14>;
			assigned-clock-rates = <0x23c34600>;
			interrupts = <0x00 0x7a 0x04>;
			clocks = <0x04 0x14>;
			interrupt-parent = <0x05>;
			compatible = "xlnx,zynqmp-dpdma";
			status = "okay";
			reg = <0x00 0xfd4c0000 0x00 0x1000>;
			phandle = <0x1a>;
			dma-channels = <0x06>;
			#dma-cells = <0x01>;
		};

		dma-controller@ffac0000 {
			power-domains = <0x12 0x2b>;
			clock-names = "clk_main\0clk_apb";
			interrupts = <0x00 0x51 0x04>;
			clocks = <0x04 0x44 0x04 0x1f>;
			interrupt-parent = <0x05>;
			xlnx,bus-width = <0x40>;
			compatible = "xlnx,zynqmp-dma-1.0";
			status = "okay";
			reg = <0x00 0xffac0000 0x00 0x1000>;
			phandle = <0x47>;
			#dma-cells = <0x01>;
		};

		gpio@ff0a0000 {
			power-domains = <0x12 0x2e>;
			gpio-controller;
			gpio-line-names = "QSPI_CLK\0QSPI_DQ1\0QSPI_DQ2\0QSPI_DQ3\0QSPI_DQ0\0QSPI_CS_B\0SPI_CLK\0LED1\0LED2\0SPI_CS_B\0SPI_MISO\0SPI_MOSI\0FWUEN\0EMMC_DAT0\0EMMC_DAT1\0EMMC_DAT2\0EMMC_DAT3\0EMMC_DAT4\0EMMC_DAT5\0EMMC_DAT6\0EMMC_DAT7\0EMMC_CMD\0EMMC_CLK\0EMMC_RST\0I2C1_SCL\0I2C1_SDA\0\0\0\0\0\0\0\0\0\0\0\0\0\0\0\0\0\0\0\0\0\0\0\0\0\0\0\0\0\0\0\0\0\0\0\0\0\0\0\0\0\0\0\0\0\0\0\0\0\0\0\0\0\0\0\0\0\0\0\0\0\0\0\0\0\0\0\0\0\0\0\0\0\0\0\0\0\0\0\0\0\0\0\0\0\0\0\0\0\0\0\0\0\0\0\0\0\0\0\0\0\0\0\0\0\0\0\0\0\0\0\0\0\0\0\0\0\0\0\0\0\0\0\0\0\0\0\0\0\0\0\0\0\0\0\0\0\0\0\0\0\0\0\0\0\0\0\0";
			interrupts = <0x00 0x10 0x04>;
			clocks = <0x04 0x1f>;
			interrupt-parent = <0x05>;
			compatible = "xlnx,zynqmp-gpio-1.0";
			#interrupt-cells = <0x02>;
			status = "okay";
			reg = <0x00 0xff0a0000 0x00 0x1000>;
			phandle = <0x14>;
			#gpio-cells = <0x02>;
			interrupt-controller;
		};

		i2c@ff020000 {
			power-domains = <0x12 0x25>;
			#address-cells = <0x01>;
			interrupts = <0x00 0x11 0x04>;
			clocks = <0x04 0x3d>;
			#size-cells = <0x00>;
			interrupt-parent = <0x05>;
			clock-frequency = <0x61a80>;
			compatible = "cdns,i2c-r1p14";
			status = "disabled";
			reg = <0x00 0xff020000 0x00 0x1000>;
			phandle = <0x51>;
		};

		dma-controller@fd520000 {
			power-domains = <0x12 0x2a>;
			iommus = <0x13 0x14ea>;
			clock-names = "clk_main\0clk_apb";
			interrupts = <0x00 0x7e 0x04>;
			clocks = <0x04 0x13 0x04 0x1f>;
			interrupt-parent = <0x05>;
			xlnx,bus-width = <0x80>;
			compatible = "xlnx,zynqmp-dma-1.0";
			status = "okay";
			reg = <0x00 0xfd520000 0x00 0x1000>;
			phandle = <0x3c>;
			#dma-cells = <0x01>;
		};

		display@fd4a0000 {
			power-domains = <0x12 0x29>;
			iommus = <0x13 0xce3>;
			phy-names = "dp-phy0\0dp-phy1";
			clock-names = "dp_apb_clk\0dp_aud_clk\0dp_vtc_pixel_clk_in";
			reg-names = "dp\0blend\0av_buf";
			assigned-clocks = <0x04 0x12 0x04 0x11 0x04 0x10>;
			u-boot,dm-pre-reloc;
			assigned-clock-rates = <0x19bfcc0 0x17d7840 0x11e1a300>;
			resets = <0x11 0x03>;
			interrupts = <0x00 0x77 0x04>;
			clocks = <0x04 0x1c 0x04 0x11 0x04 0x10>;
			interrupt-parent = <0x05>;
			dma-names = "vid0\0vid1\0vid2\0gfx0";
			compatible = "xlnx,zynqmp-dpsub-1.7";
			status = "okay";
			xlnx,dpaud-reg = <0x19>;
			phys = <0x60 0x01 0x06 0x00 0x00 0x60 0x00 0x06 0x01 0x00>;
			reg = <0x00 0xfd4a0000 0x00 0x1000 0x00 0xfd4aa000 0x00 0x1000 0x00 0xfd4ab000 0x00 0x1000>;
			phandle = <0x74>;
			dmas = <0x1a 0x00 0x1a 0x01 0x1a 0x02 0x1a 0x03>;

			i2c-bus {
			};

			zynqmp-dp-snd-pcm0 {
				dma-names = "tx";
				compatible = "xlnx,dp-snd-pcm0";
				phandle = <0x1b>;
				dmas = <0x1a 0x04>;
			};

			zynqmp-dp-snd-card {
				xlnx,dp-snd-pcm = <0x1b 0x1c>;
				xlnx,dp-snd-codec = <0x1d>;
				compatible = "xlnx,dp-snd-card";
				phandle = <0x75>;
			};

			zynqmp-dp-snd-pcm1 {
				dma-names = "tx";
				compatible = "xlnx,dp-snd-pcm1";
				phandle = <0x1c>;
				dmas = <0x1a 0x05>;
			};

			zynqmp-dp-snd-codec0 {
				clock-names = "aud_clk";
				clocks = <0x04 0x11>;
				compatible = "xlnx,dp-snd-codec";
				phandle = <0x1d>;
			};
		};

		dma-controller@ffa90000 {
			power-domains = <0x12 0x2b>;
			clock-names = "clk_main\0clk_apb";
			interrupts = <0x00 0x4e 0x04>;
			clocks = <0x04 0x44 0x04 0x1f>;
			interrupt-parent = <0x05>;
			xlnx,bus-width = <0x40>;
			compatible = "xlnx,zynqmp-dma-1.0";
			status = "okay";
			reg = <0x00 0xffa90000 0x00 0x1000>;
			phandle = <0x44>;
			#dma-cells = <0x01>;
		};

		fabric@A0000000 {
			interrupts = <0x00 0x59 0x04>;
			interrupt-parent = <0x05>;
			compatible = "generic-uio";
			reg = <0x00 0xa0000000 0x00 0x10000>;
		};

		dma-controller@fd560000 {
			power-domains = <0x12 0x2a>;
			iommus = <0x13 0x14ee>;
			clock-names = "clk_main\0clk_apb";
			interrupts = <0x00 0x82 0x04>;
			clocks = <0x04 0x13 0x04 0x1f>;
			interrupt-parent = <0x05>;
			xlnx,bus-width = <0x80>;
			compatible = "xlnx,zynqmp-dma-1.0";
			status = "okay";
			reg = <0x00 0xfd560000 0x00 0x1000>;
			phandle = <0x40>;
			#dma-cells = <0x01>;
		};

		timer@ff120000 {
			power-domains = <0x12 0x19>;
			timer-width = <0x20>;
			interrupts = <0x00 0x27 0x04 0x00 0x28 0x04 0x00 0x29 0x04>;
			clocks = <0x04 0x1f>;
			interrupt-parent = <0x05>;
			compatible = "cdns,ttc";
			status = "disabled";
			reg = <0x00 0xff120000 0x00 0x1000>;
			phandle = <0x67>;
		};

		watchdog@ff150000 {
			interrupts = <0x00 0x34 0x01>;
			clocks = <0x04 0x70>;
			interrupt-parent = <0x05>;
			timeout-sec = <0x0a>;
			compatible = "cdns,wdt-r1p2";
			status = "okay";
			reg = <0x00 0xff150000 0x00 0x1000>;
			phandle = <0x71>;
		};

		si5332_5 {
			#clock-cells = <0x00>;
			clock-frequency = <0x19bfcc0>;
			compatible = "fixed-clock";
			phandle = <0x7e>;
		};

		ethernet@ff0c0000 {
			power-domains = <0x12 0x1e>;
			iommus = <0x13 0x875>;
			#address-cells = <0x01>;
			clock-names = "pclk\0hclk\0tx_clk\0rx_clk\0tsu_clk";
			assigned-clocks = <0x04 0x2c>;
			resets = <0x11 0x1e>;
			interrupts = <0x00 0x3b 0x04 0x00 0x3b 0x04>;
			clocks = <0x04 0x1f 0x04 0x69 0x04 0x2e 0x04 0x32 0x04 0x2c>;
			#size-cells = <0x00>;
			interrupt-parent = <0x05>;
			compatible = "cdns,zynqmp-gem\0cdns,gem";
			status = "disabled";
			reg = <0x00 0xff0c0000 0x00 0x1000>;
			phandle = <0x4e>;
			reset-names = "gem1_rst";
		};

		can@ff060000 {
			power-domains = <0x12 0x2f>;
			clock-names = "can_clk\0pclk";
			resets = <0x11 0x28>;
			interrupts = <0x00 0x17 0x04>;
			clocks = <0x04 0x3f 0x04 0x1f>;
			interrupt-parent = <0x05>;
			compatible = "xlnx,zynq-can-1.0";
			status = "disabled";
			tx-fifo-depth = <0x40>;
			rx-fifo-depth = <0x40>;
			reg = <0x00 0xff060000 0x00 0x1000>;
			phandle = <0x37>;
		};

		usb@ff9e0000 {
			power-domains = <0x12 0x17>;
			#address-cells = <0x02>;
			clock-names = "bus_clk\0ref_clk";
			assigned-clocks = <0x04 0x21 0x04 0x22>;
			resets = <0x11 0x3c 0x11 0x3e 0x11 0x40>;
			clocks = <0x04 0x21 0x04 0x22>;
			#size-cells = <0x02>;
			compatible = "xlnx,zynqmp-dwc3";
			ranges;
			status = "disabled";
			reg = <0x00 0xff9e0000 0x00 0x100>;
			phandle = <0x6e>;
			reset-names = "usb_crst\0usb_hibrst\0usb_apbrst";

			usb@fe300000 {
				iommus = <0x13 0x861>;
				snps,quirk-frame-length-adjustment = <0x20>;
				snps,refclk_fladj;
				interrupts = <0x00 0x46 0x04 0x00 0x4a 0x04 0x00 0x4c 0x04>;
				clocks = <0x04 0x22>;
				interrupt-parent = <0x05>;
				compatible = "snps,dwc3";
				status = "disabled";
				interrupt-names = "dwc_usb3\0otg\0hiber";
				snps,enable_guctl1_ipd_quirk;
				snps,xhci-stream-quirk;
				reg = <0x00 0xfe300000 0x00 0x40000>;
				phandle = <0x6f>;
				snps,enable_guctl1_resume_quirk;
				snps,xhci-reset-on-resume;
			};
		};

		perf-monitor@ffa00000 {
			xlnx,metric-count-width = <0x20>;
			xlnx,have-sampled-metric-cnt = <0x01>;
			xlnx,enable-trace = <0x00>;
			xlnx,global-count-width = <0x20>;
			xlnx,enable-event-count = <0x01>;
			interrupts = <0x00 0x19 0x04>;
			clocks = <0x04 0x1f>;
			xlnx,enable-profile = <0x00>;
			xlnx,metric-count-scale = <0x01>;
			interrupt-parent = <0x05>;
			xlnx,num-monitor-slots = <0x01>;
			compatible = "xlnx,axi-perf-monitor";
			xlnx,num-of-counters = <0x08>;
			reg = <0x00 0xffa00000 0x00 0x10000>;
			phandle = <0x5b>;
			xlnx,metrics-sample-count-width = <0x20>;
			xlnx,enable-event-log = <0x01>;
		};

		dma-controller@ffad0000 {
			power-domains = <0x12 0x2b>;
			clock-names = "clk_main\0clk_apb";
			interrupts = <0x00 0x52 0x04>;
			clocks = <0x04 0x44 0x04 0x1f>;
			interrupt-parent = <0x05>;
			xlnx,bus-width = <0x40>;
			compatible = "xlnx,zynqmp-dma-1.0";
			status = "okay";
			reg = <0x00 0xffad0000 0x00 0x1000>;
			phandle = <0x48>;
			#dma-cells = <0x01>;
		};

		si5332_3 {
			#clock-cells = <0x00>;
			clock-frequency = <0x16e3600>;
			compatible = "fixed-clock";
			phandle = <0x88>;
		};

		gpu@fd4b0000 {
			power-domains = <0x12 0x3a>;
			clock-names = "gpu\0gpu_pp0\0gpu_pp1";
			interrupts = <0x00 0x84 0x04 0x00 0x84 0x04 0x00 0x84 0x04 0x00 0x84 0x04 0x00 0x84 0x04 0x00 0x84 0x04>;
			clocks = <0x04 0x18 0x04 0x19 0x04 0x1a>;
			interrupt-parent = <0x05>;
			compatible = "arm,mali-400\0arm,mali-utgard";
			status = "okay";
			interrupt-names = "IRQGP\0IRQGPMMU\0IRQPP0\0IRQPPMMU0\0IRQPP1\0IRQPPMMU1";
			reg = <0x00 0xfd4b0000 0x00 0x10000>;
			phandle = <0x42>;
		};

		dp-aud@fd4ac000 {
			compatible = "xlnx,zynqmp-dpaud-setting\0syscon";
			reg = <0x00 0xfd4ac000 0x00 0x1000>;
			phandle = <0x19>;
		};

		serial@ff000000 {
			power-domains = <0x12 0x21>;
			clock-names = "uart_clk\0pclk";
			u-boot,dm-pre-reloc;
			interrupts = <0x00 0x15 0x04>;
			clocks = <0x04 0x38 0x04 0x1f>;
			interrupt-parent = <0x05>;
			compatible = "xlnx,zynqmp-uart\0cdns,uart-r1p12";
			status = "disabled";
			reg = <0x00 0xff000000 0x00 0x1000>;
			phandle = <0x6a>;
		};

		i2c@ff030000 {
			power-domains = <0x12 0x26>;
			pinctrl-names = "default\0gpio";
			#address-cells = <0x01>;
			pinctrl-0 = <0x7b>;
			u-boot,dm-pre-reloc;
			interrupts = <0x00 0x12 0x04>;
			clocks = <0x04 0x3e>;
			#size-cells = <0x00>;
			interrupt-parent = <0x05>;
			clock-frequency = <0x61a80>;
			compatible = "cdns,i2c-r1p14";
			pinctrl-1 = <0x7c>;
			status = "okay";
			reg = <0x00 0xff030000 0x00 0x1000>;
			phandle = <0x52>;
			scl-gpios = <0x14 0x18 0x06>;
			sda-gpios = <0x14 0x19 0x06>;

			pmic@32 {
				compatible = "dlg,da9130";
				reg = <0x32>;
				phandle = <0x58>;

				regulators {

					buck1 {
						regulator-boot-on;
						regulator-always-on;
						regulator-name = "da9130_buck1";
						phandle = <0x59>;
					};
				};
			};

			eeprom@50 {
				u-boot,dm-pre-reloc;
				compatible = "st,24c64\0atmel,24c64";
				reg = <0x50>;
				phandle = <0x53>;
			};

			pmic@33 {
				compatible = "dlg,da9131";
				reg = <0x33>;
				phandle = <0x55>;

				regulators {

					buck1 {
						regulator-boot-on;
						regulator-always-on;
						regulator-name = "da9131_buck1";
						phandle = <0x56>;
					};

					buck2 {
						regulator-boot-on;
						regulator-always-on;
						regulator-name = "da9131_buck2";
						phandle = <0x57>;
					};
				};
			};

			eeprom@51 {
				u-boot,dm-pre-reloc;
				compatible = "st,24c64\0atmel,24c64";
				reg = <0x51>;
				phandle = <0x54>;
			};

			ina260@40 {
				#io-channel-cells = <0x01>;
				label = "ina260-u14";
				compatible = "ti,ina260";
				reg = <0x40>;
				phandle = <0x7d>;
			};
		};

		watchdog@fd4d0000 {
			interrupts = <0x00 0x71 0x01>;
			clocks = <0x04 0x4b>;
			interrupt-parent = <0x05>;
			timeout-sec = <0x3c>;
			reset-on-timeout;
			compatible = "cdns,wdt-r1p2";
			status = "okay";
			reg = <0x00 0xfd4d0000 0x00 0x1000>;
			phandle = <0x70>;
		};

		dma-controller@fd530000 {
			power-domains = <0x12 0x2a>;
			iommus = <0x13 0x14eb>;
			clock-names = "clk_main\0clk_apb";
			interrupts = <0x00 0x7f 0x04>;
			clocks = <0x04 0x13 0x04 0x1f>;
			interrupt-parent = <0x05>;
			xlnx,bus-width = <0x80>;
			compatible = "xlnx,zynqmp-dma-1.0";
			status = "okay";
			reg = <0x00 0xfd530000 0x00 0x1000>;
			phandle = <0x3d>;
			#dma-cells = <0x01>;
		};

		si5332_1 {
			#clock-cells = <0x00>;
			clock-frequency = <0x17d7840>;
			compatible = "fixed-clock";
			phandle = <0x86>;
		};

		phy@fd400000 {
			clock-names = "ref0\0ref1\0ref2";
			reg-names = "serdes\0siou";
			clocks = <0x7e 0x7f 0x80>;
			#phy-cells = <0x04>;
			compatible = "xlnx,zynqmp-psgtr-v1.1";
			status = "okay";
			reg = <0x00 0xfd400000 0x00 0x40000 0x00 0xfd3d0000 0x00 0x1000>;
			phandle = <0x60>;
		};

		dma-controller@fd570000 {
			power-domains = <0x12 0x2a>;
			iommus = <0x13 0x14ef>;
			clock-names = "clk_main\0clk_apb";
			interrupts = <0x00 0x83 0x04>;
			clocks = <0x04 0x13 0x04 0x1f>;
			interrupt-parent = <0x05>;
			xlnx,bus-width = <0x80>;
			compatible = "xlnx,zynqmp-dma-1.0";
			status = "okay";
			reg = <0x00 0xfd570000 0x00 0x1000>;
			phandle = <0x41>;
			#dma-cells = <0x01>;
		};

		spi@ff0f0000 {
			power-domains = <0x12 0x2d>;
			iommus = <0x13 0x873>;
			#address-cells = <0x01>;
			num-cs = <0x01>;
			clock-names = "ref_clk\0pclk";
			u-boot,dm-pre-reloc;
			is-dual = <0x00>;
			interrupts = <0x00 0x0f 0x04>;
			clocks = <0x04 0x35 0x04 0x1f>;
			#size-cells = <0x00>;
			interrupt-parent = <0x05>;
			compatible = "xlnx,zynqmp-qspi-1.0";
			status = "okay";
			reg = <0x00 0xff0f0000 0x00 0x1000 0x00 0xc0000000 0x00 0x8000000>;
			phandle = <0x5f>;

			flash@0 {
				#address-cells = <0x01>;
				spi-tx-bus-width = <0x04>;
				#size-cells = <0x01>;
				spi-max-frequency = <0x2625a00>;
				spi-rx-bus-width = <0x04>;
				compatible = "mt25qu512a\0jedec,spi-nor";
				reg = <0x00>;

				partitions {
					#address-cells = <0x01>;
					#size-cells = <0x01>;
					compatible = "fixed-partitions";

					partition@1e00000 {
						read-only;
						lock;
						label = "Recovery Image";
						reg = <0x1e00000 0x200000>;
					};

					partition@2000000 {
						read-only;
						lock;
						label = "Recovery Image Backup";
						reg = <0x2000000 0x200000>;
					};

					partition@22A0000 {
						label = "User";
						reg = <0x22a0000 0x1d60000>;
					};

					partition@1d00000 {
						label = "Open_2";
						reg = <0x1d00000 0x100000>;
					};

					partition@200000 {
						label = "Image A (FSBL, PMU, ATF, U-Boot)";
						reg = <0x200000 0xd00000>;
					};

					partition@2220000 {
						label = "U-Boot storage variables backup";
						reg = <0x2220000 0x20000>;
					};

					partition@100000 {
						label = "Persistent Register";
						reg = <0x100000 0x20000>;
					};

					partition@140000 {
						label = "Open_1";
						reg = <0x140000 0xc0000>;
					};

					partition@1c80000 {
						read-only;
						lock;
						label = "ImgSel Image B Catch";
						reg = <0x1c80000 0x80000>;
					};

					partition@0 {
						read-only;
						lock;
						label = "Image Selector";
						reg = <0x00 0x80000>;
					};

					partition@80000 {
						read-only;
						lock;
						label = "Image Selector Golden";
						reg = <0x80000 0x80000>;
					};

					partition@f00000 {
						read-only;
						lock;
						label = "ImgSel Image A Catch";
						reg = <0xf00000 0x80000>;
					};

					partition@f80000 {
						label = "Image B (FSBL, PMU, ATF, U-Boot)";
						reg = <0xf80000 0xd00000>;
					};

					partition@2200000 {
						label = "U-Boot storage variables";
						reg = <0x2200000 0x20000>;
					};

					partition@2240000 {
						read-only;
						lock;
						label = "SHA256";
						reg = <0x2240000 0x40000>;
					};

					partition@2280000 {
						label = "Secure OS Storage";
						reg = <0x2280000 0x20000>;
					};

					partition@120000 {
						label = "Persistent Register Backup";
						reg = <0x120000 0x20000>;
					};
				};
			};
		};

		timer@ff130000 {
			power-domains = <0x12 0x1a>;
			timer-width = <0x20>;
			interrupts = <0x00 0x2a 0x04 0x00 0x2b 0x04 0x00 0x2c 0x04>;
			clocks = <0x04 0x1f>;
			interrupt-parent = <0x05>;
			compatible = "cdns,ttc";
			status = "disabled";
			reg = <0x00 0xff130000 0x00 0x1000>;
			phandle = <0x68>;
		};

		spi@ff040000 {
			power-domains = <0x12 0x23>;
			#address-cells = <0x01>;
			clock-names = "ref_clk\0pclk";
			interrupts = <0x00 0x13 0x04>;
			clocks = <0x04 0x3a 0x04 0x1f>;
			#size-cells = <0x00>;
			interrupt-parent = <0x05>;
			compatible = "cdns,spi-r1p6";
			status = "disabled";
			reg = <0x00 0xff040000 0x00 0x1000>;
			phandle = <0x65>;
		};

		ina260-u14 {
			io-channels = <0x7d 0x00 0x7d 0x01 0x7d 0x02>;
			compatible = "iio-hwmon";
		};

		ethernet@ff0d0000 {
			power-domains = <0x12 0x1f>;
			iommus = <0x13 0x876>;
			#address-cells = <0x01>;
			clock-names = "pclk\0hclk\0tx_clk\0rx_clk\0tsu_clk";
			assigned-clocks = <0x04 0x2c>;
			resets = <0x11 0x1f>;
			interrupts = <0x00 0x3d 0x04 0x00 0x3d 0x04>;
			clocks = <0x04 0x1f 0x04 0x6a 0x04 0x2f 0x04 0x33 0x04 0x2c>;
			#size-cells = <0x00>;
			interrupt-parent = <0x05>;
			compatible = "cdns,zynqmp-gem\0cdns,gem";
			status = "disabled";
			reg = <0x00 0xff0d0000 0x00 0x1000>;
			phandle = <0x4f>;
			reset-names = "gem2_rst";
		};

		afi0 {
			config-afi = <0x00 0x00 0x01 0x00 0x02 0x00 0x03 0x00 0x04 0x00 0x05 0x00 0x06 0x00 0x07 0x00 0x08 0x00 0x09 0x00 0x0a 0x00 0x0b 0x00 0x0c 0x00 0x0d 0x00 0x0e 0x00 0x0f 0x00>;
			compatible = "xlnx,afi-fpga";
		};

		can@ff070000 {
			power-domains = <0x12 0x30>;
			clock-names = "can_clk\0pclk";
			resets = <0x11 0x29>;
			interrupts = <0x00 0x18 0x04>;
			clocks = <0x04 0x40 0x04 0x1f>;
			interrupt-parent = <0x05>;
			compatible = "xlnx,zynq-can-1.0";
			status = "disabled";
			tx-fifo-depth = <0x40>;
			rx-fifo-depth = <0x40>;
			reg = <0x00 0xff070000 0x00 0x1000>;
			phandle = <0x38>;
		};

		dma-controller@ffaa0000 {
			power-domains = <0x12 0x2b>;
			clock-names = "clk_main\0clk_apb";
			interrupts = <0x00 0x4f 0x04>;
			clocks = <0x04 0x44 0x04 0x1f>;
			interrupt-parent = <0x05>;
			xlnx,bus-width = <0x40>;
			compatible = "xlnx,zynqmp-dma-1.0";
			status = "okay";
			reg = <0x00 0xffaa0000 0x00 0x1000>;
			phandle = <0x45>;
			#dma-cells = <0x01>;
		};

		perf-monitor@ffa10000 {
			xlnx,metric-count-width = <0x20>;
			xlnx,have-sampled-metric-cnt = <0x01>;
			xlnx,enable-trace = <0x00>;
			xlnx,global-count-width = <0x20>;
			xlnx,enable-event-count = <0x01>;
			interrupts = <0x00 0x19 0x04>;
			clocks = <0x04 0x1f>;
			xlnx,enable-profile = <0x00>;
			xlnx,metric-count-scale = <0x01>;
			interrupt-parent = <0x05>;
			xlnx,num-monitor-slots = <0x01>;
			compatible = "xlnx,axi-perf-monitor";
			xlnx,num-of-counters = <0x08>;
			reg = <0x00 0xffa10000 0x00 0x10000>;
			phandle = <0x5e>;
			xlnx,metrics-sample-count-width = <0x20>;
			xlnx,enable-event-log = <0x01>;
		};

		mmc@ff160000 {
			power-domains = <0x12 0x27>;
			iommus = <0x13 0x870>;
			pinctrl-names = "default";
			clock-output-names = "clk_out_sd0\0clk_in_sd0";
			xlnx,mio-bank = <0x00>;
			pinctrl-0 = <0x17>;
			clock-names = "clk_xin\0clk_ahb";
			assigned-clocks = <0x04 0x36>;
			bus-width = <0x08>;
			non-removable;
			u-boot,dm-pre-reloc;
			assigned-clock-rates = <0xb2cfe8b>;
			resets = <0x11 0x26>;
			interrupts = <0x00 0x30 0x04>;
			clocks = <0x04 0x36 0x04 0x1f>;
			#clock-cells = <0x01>;
			interrupt-parent = <0x05>;
			compatible = "xlnx,zynqmp-8.9a\0arasan,sdhci-8.9a";
			status = "disabled";
			disable-wp;
			reg = <0x00 0xff160000 0x00 0x1000>;
			phandle = <0x63>;
		};

		dma-controller@ffae0000 {
			power-domains = <0x12 0x2b>;
			clock-names = "clk_main\0clk_apb";
			interrupts = <0x00 0x53 0x04>;
			clocks = <0x04 0x44 0x04 0x1f>;
			interrupt-parent = <0x05>;
			xlnx,bus-width = <0x40>;
			compatible = "xlnx,zynqmp-dma-1.0";
			status = "okay";
			reg = <0x00 0xffae0000 0x00 0x1000>;
			phandle = <0x49>;
			#dma-cells = <0x01>;
		};

		perf-monitor@fd490000 {
			xlnx,metric-count-width = <0x20>;
			xlnx,have-sampled-metric-cnt = <0x01>;
			xlnx,enable-trace = <0x00>;
			xlnx,global-count-width = <0x20>;
			xlnx,enable-event-count = <0x01>;
			interrupts = <0x00 0x7b 0x04>;
			clocks = <0x04 0x1c>;
			xlnx,enable-profile = <0x00>;
			xlnx,metric-count-scale = <0x01>;
			interrupt-parent = <0x05>;
			xlnx,num-monitor-slots = <0x01>;
			compatible = "xlnx,axi-perf-monitor";
			xlnx,num-of-counters = <0x08>;
			reg = <0x00 0xfd490000 0x00 0x10000>;
			phandle = <0x5d>;
			xlnx,metrics-sample-count-width = <0x20>;
			xlnx,enable-event-log = <0x00>;
		};

		serial@ff010000 {
			power-domains = <0x12 0x22>;
			pinctrl-names = "default";
			pinctrl-0 = <0x85>;
			clock-names = "uart_clk\0pclk";
			u-boot,dm-pre-reloc;
			interrupts = <0x00 0x16 0x04>;
			clocks = <0x04 0x39 0x04 0x1f>;
			interrupt-parent = <0x05>;
			compatible = "xlnx,zynqmp-uart\0cdns,uart-r1p12";
			status = "okay";
			reg = <0x00 0xff010000 0x00 0x1000>;
			phandle = <0x6b>;
		};

		zyxclmm_drm {
			compatible = "xlnx,zocl";
			status = "okay";
		};

		dma-controller@fd500000 {
			power-domains = <0x12 0x2a>;
			iommus = <0x13 0x14e8>;
			clock-names = "clk_main\0clk_apb";
			interrupts = <0x00 0x7c 0x04>;
			clocks = <0x04 0x13 0x04 0x1f>;
			interrupt-parent = <0x05>;
			xlnx,bus-width = <0x80>;
			compatible = "xlnx,zynqmp-dma-1.0";
			status = "okay";
			reg = <0x00 0xfd500000 0x00 0x1000>;
			phandle = <0x3a>;
			#dma-cells = <0x01>;
		};

		ahci@fd0c0000 {
			power-domains = <0x12 0x1c>;
			resets = <0x11 0x10>;
			interrupts = <0x00 0x85 0x04>;
			clocks = <0x04 0x16>;
			interrupt-parent = <0x05>;
			compatible = "ceva,ahci-1v84";
			status = "disabled";
			reg = <0x00 0xfd0c0000 0x00 0x2000>;
			phandle = <0x62>;
		};

		cci@fd6e0000 {
			#address-cells = <0x01>;
			#size-cells = <0x01>;
			compatible = "arm,cci-400";
			ranges = <0x00 0x00 0xfd6e0000 0x10000>;
			status = "disabled";
			reg = <0x00 0xfd6e0000 0x00 0x9000>;
			phandle = <0x39>;

			pmu@9000 {
				interrupts = <0x00 0x7b 0x04 0x00 0x7b 0x04 0x00 0x7b 0x04 0x00 0x7b 0x04 0x00 0x7b 0x04>;
				interrupt-parent = <0x05>;
				compatible = "arm,cci-400-pmu,r1";
				reg = <0x9000 0x5000>;
			};
		};

		dma-controller@fd540000 {
			power-domains = <0x12 0x2a>;
			iommus = <0x13 0x14ec>;
			clock-names = "clk_main\0clk_apb";
			interrupts = <0x00 0x80 0x04>;
			clocks = <0x04 0x13 0x04 0x1f>;
			interrupt-parent = <0x05>;
			xlnx,bus-width = <0x80>;
			compatible = "xlnx,zynqmp-dma-1.0";
			status = "okay";
			reg = <0x00 0xfd540000 0x00 0x1000>;
			phandle = <0x3e>;
			#dma-cells = <0x01>;
		};

		pcie@fd0e0000 {
			power-domains = <0x12 0x3b>;
			iommus = <0x13 0x4d0>;
			#address-cells = <0x03>;
			bus-range = <0x00 0xff>;
			reg-names = "breg\0pcireg\0cfg";
			interrupts = <0x00 0x76 0x04 0x00 0x75 0x04 0x00 0x74 0x04 0x00 0x73 0x04 0x00 0x72 0x04>;
			clocks = <0x04 0x17>;
			interrupt-map = <0x00 0x00 0x00 0x01 0x16 0x01 0x00 0x00 0x00 0x02 0x16 0x02 0x00 0x00 0x00 0x03 0x16 0x03 0x00 0x00 0x00 0x04 0x16 0x04>;
			#size-cells = <0x02>;
			interrupt-parent = <0x05>;
			msi-controller;
			device_type = "pci";
			interrupt-map-mask = <0x00 0x00 0x00 0x07>;
			compatible = "xlnx,nwl-pcie-2.11";
			ranges = <0x2000000 0x00 0xe0000000 0x00 0xe0000000 0x00 0x10000000 0x43000000 0x06 0x00 0x06 0x00 0x02 0x00>;
			#interrupt-cells = <0x01>;
			status = "disabled";
			interrupt-names = "misc\0dummy\0intx\0msi1\0msi0";
			reg = <0x00 0xfd0e0000 0x00 0x1000 0x00 0xfd480000 0x00 0x1000 0x80 0x00 0x00 0x10000000>;
			phandle = <0x15>;
			msi-parent = <0x15>;

			legacy-interrupt-controller {
				#address-cells = <0x00>;
				#interrupt-cells = <0x01>;
				phandle = <0x16>;
				interrupt-controller;
			};
		};
	};
};
